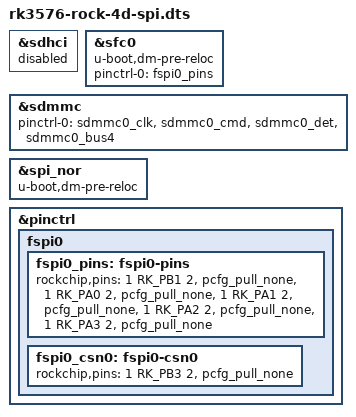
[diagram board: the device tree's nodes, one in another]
// SPDX-License-Identifier: (GPL-2.0+ OR MIT)
/*
 * Copyright (c) 2024 Rockchip Electronics Co., Ltd.
 * Copyright (c) 2024 Radxa Computer (Shenzhen) Co., Ltd.
 */

/dts-v1/;

#include "rk3576-rock-4d.dts"

&sdhci {
	status = "disabled";
};

&sfc0 {
	status = "okay";
	u-boot,dm-pre-reloc;
	pinctrl-names = "default";
	pinctrl-0 = <&fspi0_pins>;
};

&sdmmc {
	pinctrl-names = "default";
	pinctrl-0 = <&sdmmc0_clk &sdmmc0_cmd &sdmmc0_det &sdmmc0_bus4>;
};

&spi_nor {
	status = "okay";
	u-boot,dm-pre-reloc;
};

&pinctrl {

	/delete-node/ fspi0;
	fspi0 {
		u-boot,dm-spl;
		fspi0_pins: fspi0-pins {
			u-boot,dm-spl;
			rockchip,pins =
				/* fspi0_clk */
				<1 RK_PB1 2 &pcfg_pull_none>,
				/* fspi0_d0 */
				<1 RK_PA0 2 &pcfg_pull_none>,
				/* fspi0_d1 */
				<1 RK_PA1 2 &pcfg_pull_none>,
				/* fspi0_d2 */
				<1 RK_PA2 2 &pcfg_pull_none>,
				/* fspi0_d3 */
				<1 RK_PA3 2 &pcfg_pull_none>;
		};

		fspi0_csn0: fspi0-csn0 {
			u-boot,dm-spl;
			rockchip,pins =
				/* fspi0_csn0 */
				<1 RK_PB3 2 &pcfg_pull_none>;
		};
	};
};
